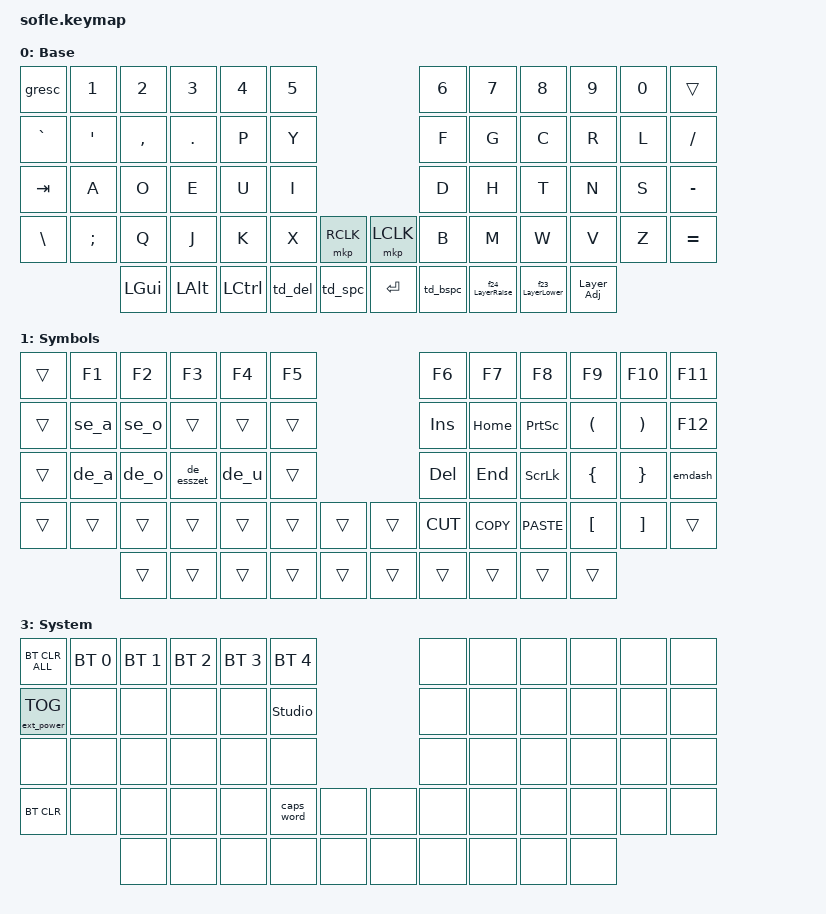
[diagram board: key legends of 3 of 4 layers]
/*
 * Copyright (c) 2020 The ZMK Contributors
 *
 * SPDX-License-Identifier: MIT
 */

#include "keys_se.h"
#include "keys_de.h"
#include "keys_syr.h"
#include "keys_ru.h"
#include <behaviors.dtsi>
#include <dt-bindings/zmk/bt.h>
#include <dt-bindings/zmk/ext_power.h>
#include <dt-bindings/zmk/keys.h>
#include <dt-bindings/zmk/pointing.h>

// Encoders

&sensors { triggers-per-rotation = <30>; };

&left_encoder { steps = <90>; };

&right_encoder { steps = <90>; };

#define BASE 0
#define LOWER 1
#define RAISE 2
#define ADJUST 3

/ {
    // Activate ADJUST layer by pressing raise and lower

    conditional_layers {
        compatible = "zmk,conditional-layers";

        adjust_layer {
            if-layers = <1 2>;
            then-layer = <4>;
        };
    };

    combos {
        compatible = "zmk,combos";

        esc {
            bindings = <&kp ESCAPE>;
            key-positions = <15 14>;
        };
    };

    behaviors {
        caps: caps {
            compatible = "zmk,behavior-caps-word";
            label = "CAPS";
            #binding-cells = <0>;
            continue-list = <POUND MINUS BACKSPACE UNDERSCORE>;
        };

        sp_sh: space_shift {
            compatible = "zmk,behavior-hold-tap";
            #binding-cells = <2>;
            tapping-term-ms = <100>;
            flavor = "balanced";
            bindings = <&kp>, <&kp>;
        };

        td_spc: tap_dance_space {
            compatible = "zmk,behavior-tap-dance";
            #binding-cells = <0>;
            tapping-term-ms = <100>;
            bindings = <&sp_sh LSHFT SPACE>, <&kp CAPS>;
        };

        // Hold-tap for delete: hold = repeat delete, tap = pass through

        ht_del: hold_tap_delete {
            compatible = "zmk,behavior-hold-tap";
            #binding-cells = <2>;
            tapping-term-ms = <200>;
            flavor = "tap-preferred";
            bindings = <&kp>, <&kp>;
        };

        // Tap-dance for delete: tap = DEL, double-tap = Ctrl+DEL

        td_del: tap_dance_delete {
            compatible = "zmk,behavior-tap-dance";
            #binding-cells = <0>;
            tapping-term-ms = <170>;
            bindings = <&ht_del DEL DEL>, <&kp LC(DEL)>;
        };

        // Tap-dance for backspace: tap = BSPC, double-tap = Ctrl+BSPC

        td_bspc: tap_dance_backspace {
            compatible = "zmk,behavior-tap-dance";
            #binding-cells = <0>;
            tapping-term-ms = <150>;
            bindings = <&ht_del BSPC BSPC>, <&kp LC(BSPC)>;
        };
    };

    macros {
        de_a: de_a {
            compatible = "zmk,behavior-macro";
            #binding-cells = <0>;
            bindings = <&kp RIGHT_ALT &kp A>;
            label = "DE_A";
        };

        de_o: de_o {
            compatible = "zmk,behavior-macro";
            #binding-cells = <0>;
            bindings = <&kp RIGHT_ALT &kp O>;
            label = "DE_O";
        };

        de_esszet: de_esszet {
            compatible = "zmk,behavior-macro";
            #binding-cells = <0>;
            bindings = <&kp RIGHT_ALT &kp E>;
            label = "DE_ESSZET";
        };

        de_u: de_u {
            compatible = "zmk,behavior-macro";
            #binding-cells = <0>;
            bindings = <&kp RIGHT_ALT &kp U>;
            label = "DE_U";
        };

        se_o: se_o {
            compatible = "zmk,behavior-macro";
            #binding-cells = <0>;
            bindings = <&kp RIGHT_ALT &kp PERIOD &kp O>;
            label = "SE_O";
        };

        se_a: se_a {
            compatible = "zmk,behavior-macro";
            #binding-cells = <0>;
            bindings = <&kp RIGHT_ALT &kp PERIOD &kp A>;
            label = "SE_A";
        };

        // Letters A-Z

        as_a: as_a {
            compatible = "zmk,behavior-macro";
            #binding-cells = <0>;
            bindings = <&kp LEFT_ALT &kp LEFT_SHIFT &kp A>;
            label = "AS_A";
        };

        as_b: as_b {
            compatible = "zmk,behavior-macro";
            #binding-cells = <0>;
            bindings = <&kp LEFT_ALT &kp LEFT_SHIFT &kp B>;
            label = "AS_B";
        };

        as_c: as_c {
            compatible = "zmk,behavior-macro";
            #binding-cells = <0>;
            bindings = <&kp LEFT_ALT &kp LEFT_SHIFT &kp C>;
            label = "AS_C";
        };

        as_d: as_d {
            compatible = "zmk,behavior-macro";
            #binding-cells = <0>;
            bindings = <&kp LEFT_ALT &kp LEFT_SHIFT &kp D>;
            label = "AS_D";
        };

        as_e: as_e {
            compatible = "zmk,behavior-macro";
            #binding-cells = <0>;
            bindings = <&kp LEFT_ALT &kp LEFT_SHIFT &kp E>;
            label = "AS_E";
        };

        as_f: as_f {
            compatible = "zmk,behavior-macro";
            #binding-cells = <0>;
            bindings = <&kp LEFT_ALT &kp LEFT_SHIFT &kp F>;
            label = "AS_F";
        };

        as_g: as_g {
            compatible = "zmk,behavior-macro";
            #binding-cells = <0>;
            bindings = <&kp LEFT_ALT &kp LEFT_SHIFT &kp G>;
            label = "AS_G";
        };

        as_h: as_h {
            compatible = "zmk,behavior-macro";
            #binding-cells = <0>;
            bindings = <&kp LEFT_ALT &kp LEFT_SHIFT &kp H>;
            label = "AS_H";
        };

        as_i: as_i {
            compatible = "zmk,behavior-macro";
            #binding-cells = <0>;
            bindings = <&kp LEFT_ALT &kp LEFT_SHIFT &kp I>;
            label = "AS_I";
        };

        as_j: as_j {
            compatible = "zmk,behavior-macro";
            #binding-cells = <0>;
            bindings = <&kp LEFT_ALT &kp LEFT_SHIFT &kp J>;
            label = "AS_J";
        };

        as_k: as_k {
            compatible = "zmk,behavior-macro";
            #binding-cells = <0>;
            bindings = <&kp LEFT_ALT &kp LEFT_SHIFT &kp K>;
            label = "AS_K";
        };

        as_l: as_l {
            compatible = "zmk,behavior-macro";
            #binding-cells = <0>;
            bindings = <&kp LEFT_ALT &kp LEFT_SHIFT &kp L>;
            label = "AS_L";
        };

        as_m: as_m {
            compatible = "zmk,behavior-macro";
            #binding-cells = <0>;
            bindings = <&kp LEFT_ALT &kp LEFT_SHIFT &kp M>;
            label = "AS_M";
        };

        as_n: as_n {
            compatible = "zmk,behavior-macro";
            #binding-cells = <0>;
            bindings = <&kp LEFT_ALT &kp LEFT_SHIFT &kp N>;
            label = "AS_N";
        };

        as_o: as_o {
            compatible = "zmk,behavior-macro";
            #binding-cells = <0>;
            bindings = <&kp LEFT_ALT &kp LEFT_SHIFT &kp O>;
            label = "AS_O";
        };

        as_p: as_p {
            compatible = "zmk,behavior-macro";
            #binding-cells = <0>;
            bindings = <&kp LEFT_ALT &kp LEFT_SHIFT &kp P>;
            label = "AS_P";
        };

        as_q: as_q {
            compatible = "zmk,behavior-macro";
            #binding-cells = <0>;
            bindings = <&kp LEFT_ALT &kp LEFT_SHIFT &kp Q>;
            label = "AS_Q";
        };

        as_r: as_r {
            compatible = "zmk,behavior-macro";
            #binding-cells = <0>;
            bindings = <&kp LEFT_ALT &kp LEFT_SHIFT &kp R>;
            label = "AS_R";
        };

        as_s: as_s {
            compatible = "zmk,behavior-macro";
            #binding-cells = <0>;
            bindings = <&kp LEFT_ALT &kp LEFT_SHIFT &kp S>;
            label = "AS_S";
        };

        as_t: as_t {
            compatible = "zmk,behavior-macro";
            #binding-cells = <0>;
            bindings = <&kp LEFT_ALT &kp LEFT_SHIFT &kp T>;
            label = "AS_T";
        };

        as_u: as_u {
            compatible = "zmk,behavior-macro";
            #binding-cells = <0>;
            bindings = <&kp LEFT_ALT &kp LEFT_SHIFT &kp U>;
            label = "AS_U";
        };

        as_v: as_v {
            compatible = "zmk,behavior-macro";
            #binding-cells = <0>;
            bindings = <&kp LEFT_ALT &kp LEFT_SHIFT &kp V>;
            label = "AS_V";
        };

        as_w: as_w {
            compatible = "zmk,behavior-macro";
            #binding-cells = <0>;
            bindings = <&kp LEFT_ALT &kp LEFT_SHIFT &kp W>;
            label = "AS_W";
        };

        as_x: as_x {
            compatible = "zmk,behavior-macro";
            #binding-cells = <0>;
            bindings = <&kp LEFT_ALT &kp LEFT_SHIFT &kp X>;
            label = "AS_X";
        };

        as_y: as_y {
            compatible = "zmk,behavior-macro";
            #binding-cells = <0>;
            bindings = <&kp LEFT_ALT &kp LEFT_SHIFT &kp Y>;
            label = "AS_Y";
        };

        as_z: as_z {
            compatible = "zmk,behavior-macro";
            #binding-cells = <0>;
            bindings = <&kp LEFT_ALT &kp LEFT_SHIFT &kp Z>;
            label = "AS_Z";
        };

        // Numbers 0-9

        as_1: as_1 {
            compatible = "zmk,behavior-macro";
            #binding-cells = <0>;
            bindings = <&kp LEFT_ALT &kp LEFT_SHIFT &kp N1>;
            label = "AS_1";
        };

        as_2: as_2 {
            compatible = "zmk,behavior-macro";
            #binding-cells = <0>;
            bindings = <&kp LEFT_ALT &kp LEFT_SHIFT &kp N2>;
            label = "AS_2";
        };

        as_3: as_3 {
            compatible = "zmk,behavior-macro";
            #binding-cells = <0>;
            bindings = <&kp LEFT_ALT &kp LEFT_SHIFT &kp N3>;
            label = "AS_3";
        };

        as_4: as_4 {
            compatible = "zmk,behavior-macro";
            #binding-cells = <0>;
            bindings = <&kp LEFT_ALT &kp LEFT_SHIFT &kp N4>;
            label = "AS_4";
        };

        as_5: as_5 {
            compatible = "zmk,behavior-macro";
            #binding-cells = <0>;
            bindings = <&kp LEFT_ALT &kp LEFT_SHIFT &kp N5>;
            label = "AS_5";
        };

        as_6: as_6 {
            compatible = "zmk,behavior-macro";
            #binding-cells = <0>;
            bindings = <&kp LEFT_ALT &kp LEFT_SHIFT &kp N6>;
            label = "AS_6";
        };

        as_7: as_7 {
            compatible = "zmk,behavior-macro";
            #binding-cells = <0>;
            bindings = <&kp LEFT_ALT &kp LEFT_SHIFT &kp N7>;
            label = "AS_7";
        };

        as_8: as_8 {
            compatible = "zmk,behavior-macro";
            #binding-cells = <0>;
            bindings = <&kp LEFT_ALT &kp LEFT_SHIFT &kp N8>;
            label = "AS_8";
        };

        as_9: as_9 {
            compatible = "zmk,behavior-macro";
            #binding-cells = <0>;
            bindings = <&kp LEFT_ALT &kp LEFT_SHIFT &kp N9>;
            label = "AS_9";
        };

        as_0: as_0 {
            compatible = "zmk,behavior-macro";
            #binding-cells = <0>;
            bindings = <&kp LEFT_ALT &kp LEFT_SHIFT &kp N0>;
            label = "AS_0";
        };

        // Symbol keys

        as_minus: as_minus {
            compatible = "zmk,behavior-macro";
            #binding-cells = <0>;
            bindings = <&kp LEFT_ALT &kp LEFT_SHIFT &kp MINUS>;
            label = "AS_MINUS";
        };

        as_equal: as_equal {
            compatible = "zmk,behavior-macro";
            #binding-cells = <0>;
            bindings = <&kp LEFT_ALT &kp LEFT_SHIFT &kp EQUAL>;
            label = "AS_EQUAL";
        };

        as_lbkt: as_lbkt {
            compatible = "zmk,behavior-macro";
            #binding-cells = <0>;
            bindings = <&kp LEFT_ALT &kp LEFT_SHIFT &kp LBKT>;
            label = "AS_LBKT";
        };

        as_rbkt: as_rbkt {
            compatible = "zmk,behavior-macro";
            #binding-cells = <0>;
            bindings = <&kp LEFT_ALT &kp LEFT_SHIFT &kp RBKT>;
            label = "AS_RBKT";
        };

        as_bslh: as_bslh {
            compatible = "zmk,behavior-macro";
            #binding-cells = <0>;
            bindings = <&kp LEFT_ALT &kp LEFT_SHIFT &kp BSLH>;
            label = "AS_BSLH";
        };

        as_semi: as_semi {
            compatible = "zmk,behavior-macro";
            #binding-cells = <0>;
            bindings = <&kp LEFT_ALT &kp LEFT_SHIFT &kp SEMI>;
            label = "AS_SEMI";
        };

        as_sqt: as_sqt {
            compatible = "zmk,behavior-macro";
            #binding-cells = <0>;
            bindings = <&kp LEFT_ALT &kp LEFT_SHIFT &kp SQT>;
            label = "AS_SQT";
        };

        as_grave: as_grave {
            compatible = "zmk,behavior-macro";
            #binding-cells = <0>;
            bindings = <&kp LEFT_ALT &kp LEFT_SHIFT &kp GRAVE>;
            label = "AS_GRAVE";
        };

        as_comma: as_comma {
            compatible = "zmk,behavior-macro";
            #binding-cells = <0>;
            bindings = <&kp LEFT_ALT &kp LEFT_SHIFT &kp COMMA>;
            label = "AS_COMMA";
        };

        as_period: as_period {
            compatible = "zmk,behavior-macro";
            #binding-cells = <0>;
            bindings = <&kp LEFT_ALT &kp LEFT_SHIFT &kp PERIOD>;
            label = "AS_PERIOD";
        };

        as_slash: as_slash {
            compatible = "zmk,behavior-macro";
            #binding-cells = <0>;
            bindings = <&kp LEFT_ALT &kp LEFT_SHIFT &kp SLASH>;
            label = "AS_SLASH";
        };

        // Function keys F1-F12

        as_f1: as_f1 {
            compatible = "zmk,behavior-macro";
            #binding-cells = <0>;
            bindings = <&kp LEFT_ALT &kp LEFT_SHIFT &kp F1>;
            label = "AS_F1";
        };

        as_f2: as_f2 {
            compatible = "zmk,behavior-macro";
            #binding-cells = <0>;
            bindings = <&kp LEFT_ALT &kp LEFT_SHIFT &kp F2>;
            label = "AS_F2";
        };

        as_f3: as_f3 {
            compatible = "zmk,behavior-macro";
            #binding-cells = <0>;
            bindings = <&kp LEFT_ALT &kp LEFT_SHIFT &kp F3>;
            label = "AS_F3";
        };

        as_f4: as_f4 {
            compatible = "zmk,behavior-macro";
            #binding-cells = <0>;
            bindings = <&kp LEFT_ALT &kp LEFT_SHIFT &kp F4>;
            label = "AS_F4";
        };

        as_f5: as_f5 {
            compatible = "zmk,behavior-macro";
            #binding-cells = <0>;
            bindings = <&kp LEFT_ALT &kp LEFT_SHIFT &kp F5>;
            label = "AS_F5";
        };

        as_f6: as_f6 {
            compatible = "zmk,behavior-macro";
            #binding-cells = <0>;
            bindings = <&kp LEFT_ALT &kp LEFT_SHIFT &kp F6>;
            label = "AS_F6";
        };

        as_f7: as_f7 {
            compatible = "zmk,behavior-macro";
            #binding-cells = <0>;
            bindings = <&kp LEFT_ALT &kp LEFT_SHIFT &kp F7>;
            label = "AS_F7";
        };

        as_f8: as_f8 {
            compatible = "zmk,behavior-macro";
            #binding-cells = <0>;
            bindings = <&kp LEFT_ALT &kp LEFT_SHIFT &kp F8>;
            label = "AS_F8";
        };

        as_f9: as_f9 {
            compatible = "zmk,behavior-macro";
            #binding-cells = <0>;
            bindings = <&kp LEFT_ALT &kp LEFT_SHIFT &kp F9>;
            label = "AS_F9";
        };

        as_f10: as_f10 {
            compatible = "zmk,behavior-macro";
            #binding-cells = <0>;
            bindings = <&kp LEFT_ALT &kp LEFT_SHIFT &kp F10>;
            label = "AS_F10";
        };

        as_f11: as_f11 {
            compatible = "zmk,behavior-macro";
            #binding-cells = <0>;
            bindings = <&kp LEFT_ALT &kp LEFT_SHIFT &kp F11>;
            label = "AS_F11";
        };

        as_f12: as_f12 {
            compatible = "zmk,behavior-macro";
            #binding-cells = <0>;
            bindings = <&kp LEFT_ALT &kp LEFT_SHIFT &kp F12>;
            label = "AS_F12";
        };

        // Special keys

        as_tab: as_tab {
            compatible = "zmk,behavior-macro";
            #binding-cells = <0>;
            bindings = <&kp LEFT_ALT &kp LEFT_SHIFT &kp TAB>;
            label = "AS_TAB";
        };

        as_space: as_space {
            compatible = "zmk,behavior-macro";
            #binding-cells = <0>;
            bindings = <&kp LEFT_ALT &kp LEFT_SHIFT &kp SPACE>;
            label = "AS_SPACE";
        };

        as_enter: as_enter {
            compatible = "zmk,behavior-macro";
            #binding-cells = <0>;
            bindings = <&kp LEFT_ALT &kp LEFT_SHIFT &kp ENTER>;
            label = "AS_ENTER";
        };

        as_bspc: as_bspc {
            compatible = "zmk,behavior-macro";
            #binding-cells = <0>;
            bindings = <&kp LEFT_ALT &kp LEFT_SHIFT &kp BSPC>;
            label = "AS_BSPC";
        };

        as_del: as_del {
            compatible = "zmk,behavior-macro";
            #binding-cells = <0>;
            bindings = <&kp LEFT_ALT &kp LEFT_SHIFT &kp DEL>;
            label = "AS_DEL";
        };

        as_esc: as_esc {
            compatible = "zmk,behavior-macro";
            #binding-cells = <0>;
            bindings = <&kp LEFT_ALT &kp LEFT_SHIFT &kp ESC>;
            label = "AS_ESC";
        };

        // Arrow keys

        as_up: as_up {
            compatible = "zmk,behavior-macro";
            #binding-cells = <0>;
            bindings = <&kp LEFT_ALT &kp LEFT_SHIFT &kp UP>;
            label = "AS_UP";
        };

        as_down: as_down {
            compatible = "zmk,behavior-macro";
            #binding-cells = <0>;
            bindings = <&kp LEFT_ALT &kp LEFT_SHIFT &kp DOWN>;
            label = "AS_DOWN";
        };

        as_left: as_left {
            compatible = "zmk,behavior-macro";
            #binding-cells = <0>;
            bindings = <&kp LEFT_ALT &kp LEFT_SHIFT &kp LEFT>;
            label = "AS_LEFT";
        };

        as_right: as_right {
            compatible = "zmk,behavior-macro";
            #binding-cells = <0>;
            bindings = <&kp LEFT_ALT &kp LEFT_SHIFT &kp RIGHT>;
            label = "AS_RIGHT";
        };

        // Page/Home/End keys

        as_home: as_home {
            compatible = "zmk,behavior-macro";
            #binding-cells = <0>;
            bindings = <&kp LEFT_ALT &kp LEFT_SHIFT &kp HOME>;
            label = "AS_HOME";
        };

        as_end: as_end {
            compatible = "zmk,behavior-macro";
            #binding-cells = <0>;
            bindings = <&kp LEFT_ALT &kp LEFT_SHIFT &kp END>;
            label = "AS_END";
        };

        as_pg_up: as_pg_up {
            compatible = "zmk,behavior-macro";
            #binding-cells = <0>;
            bindings = <&kp LEFT_ALT &kp LEFT_SHIFT &kp PG_UP>;
            label = "AS_PG_UP";
        };

        as_pg_dn: as_pg_dn {
            compatible = "zmk,behavior-macro";
            #binding-cells = <0>;
            bindings = <&kp LEFT_ALT &kp LEFT_SHIFT &kp PG_DN>;
            label = "AS_PG_DN";
        };

        // Insert key

        as_ins: as_ins {
            compatible = "zmk,behavior-macro";
            #binding-cells = <0>;
            bindings = <&kp LEFT_ALT &kp LEFT_SHIFT &kp INS>;
            label = "AS_INS";
        };

        altf4: altf4 {
            compatible = "zmk,behavior-macro";
            #binding-cells = <0>;
            bindings = <&kp LEFT_ALT &kp F4>;
            label = "ALTF4";
        };

        altf2: altf2 {
            compatible = "zmk,behavior-macro";
            #binding-cells = <0>;
            bindings = <&kp LEFT_ALT &kp F2>;
            label = "ALTF2";
        };

        emdash: emdash {
            compatible = "zmk,behavior-macro";
            #binding-cells = <0>;
            bindings = <&kp RIGHT_ALT &kp MINUS>;
            label = "EMDASH";
        };

        f24_LayerRaise: f24_LayerRaise {
            compatible = "zmk,behavior-macro";
            #binding-cells = <0>;
            bindings =
                <&macro_press>,
                <&kp F24>,
                <&macro_press>,
                <&mo 1>,
                <&macro_pause_for_release>,
                <&macro_release>,
                <&mo 1>,
                <&macro_release>,
                <&kp F24>;

            label = "F24_LAYERRAISE";
        };

        f23_LayerLower: f23_LayerLower {
            compatible = "zmk,behavior-macro";
            #binding-cells = <0>;
            bindings =
                <&macro_press>,
                <&kp F23>,
                <&macro_press>,
                <&mo 2>,
                <&macro_pause_for_release>,
                <&macro_release>,
                <&mo 2>,
                <&macro_release>,
                <&kp F23>;

            label = "F23_LAYERLOWER";
        };

        Layer_Adj: Layer_Adj {
            compatible = "zmk,behavior-macro";
            #binding-cells = <0>;
            bindings =
                <&macro_press>,
                <&kp F22>,
                <&macro_press>,
                <&mo 3>,
                <&macro_pause_for_release>,
                <&macro_release>,
                <&mo 3>,
                <&macro_release>,
                <&kp F22>;

            label = "LAYER_ADJ";
        };
    };

    keymap {
        compatible = "zmk,keymap";

        default_layer {
            display-name = "Base";

            // ------------------------------------------------------------------------------------------------------------
            // |   `   |  1  |  2  |  3   |  4   |  5   |                   |  6   |  7    |  8    |  9   |   0   |       |
            // |  ESC  |  Q  |  W  |  E   |  R   |  T   |                   |  Y   |  U    |  I    |  O   |   P   | BKSPC |
            // |  TAB  |  A  |  S  |  D   |  F   |  G   |                   |  H   |  J    |  K    |  L   |   ;   |   '   |
            // | SHIFT |  Z  |  X  |  C   |  V   |  B   |  MUTE  |  |       |  N   |  M    |  ,    |  .   |   /   | SHIFT |
            //               | GUI | ALT  | CTRL | LOWER|  ENTER |  | SPACE | RAISE| CTRL  | ALT   | GUI  |

            bindings = <
&gresc         &kp N1    &kp N2     &kp N3      &kp N4     &kp N5                           &kp N6    &kp N7           &kp N8           &kp N9      &kp N0  &trans
&kp GRAVE      &kp APOS  &kp COMMA  &kp PERIOD  &kp P      &kp Y                            &kp F     &kp G            &kp C            &kp R       &kp L   &kp FSLH
&kp TAB        &kp A     &kp O      &kp E       &kp U      &kp I                            &kp D     &kp H            &kp T            &kp N       &kp S   &kp MINUS
&kp BACKSLASH  &kp SEMI  &kp Q      &kp J       &kp K      &kp X    &mkp RCLK    &mkp LCLK  &kp B     &kp M            &kp W            &kp V       &kp Z   &kp EQUAL
                         &kp LGUI   &kp LALT    &kp LCTRL  &td_del  &td_spc      &kp ENTER  &td_bspc  &f24_LayerRaise  &f23_LayerLower  &Layer_Adj
            >;

            sensor-bindings =
                <&inc_dec_kp RIGHT_ARROW LEFT_ARROW>,
                <&inc_dec_kp DOWN_ARROW UP_ARROW>;
        };

        lower_layer {
            display-name = "Symbols";

            // TODO: Some binds are waiting for shifted keycode support.
            // ------------------------------------------------------------------------------------------------------------
            // |       |  F1 |  F2 |  F3  |  F4  |  F5  |                   |  F6  |  F7   |  F8   |  F9  |  F10  |  F11  |
            // |   `   |  1  |  2  |  3   |  4   |  5   |                   |  6   |  7    |  8    |  9   |   0   |  F12  |
            // |       |  !  |  @  |  #   |  $   |  %   |                   |  ^   |  &    |  *    |  (   |   )   |   |   |
            // |       |  =  |  -  |  +   |  {   |  }   |        |  |       |  [   |  ]    |  ;    |  :   |   \   |       |
            //               |     |      |      |      |        |  |       |      |       |       |      |

            bindings = <
&trans  &kp F1  &kp F2  &kp F3      &kp F4  &kp F5                    &kp F6      &kp F7      &kp F8           &kp F9                &kp F10                &kp F11
&trans  &se_a   &se_o   &trans      &trans  &trans                    &kp INS     &kp HOME    &kp PRINTSCREEN  &kp LEFT_PARENTHESIS  &kp RIGHT_PARENTHESIS  &kp F12
&trans  &de_a   &de_o   &de_esszet  &de_u   &trans                    &kp DELETE  &kp END     &kp SCROLLLOCK   &kp LEFT_BRACE        &kp RIGHT_BRACE        &emdash
&trans  &trans  &trans  &trans      &trans  &trans  &trans    &trans  &kp K_CUT   &kp K_COPY  &kp K_PASTE      &kp LEFT_BRACKET      &kp RIGHT_BRACKET      &trans
                &trans  &trans      &trans  &trans  &trans    &trans  &trans      &trans      &trans           &trans
            >;

            sensor-bindings =
                <&inc_dec_kp K_UNDO K_REDO>,
                <&inc_dec_kp PAGE_UP PAGE_DOWN>;
        };

        raise_layer {
            display-name = "stinkybutts";

            // ------------------------------------------------------------------------------------------------------------
            // | BTCLR | BT1  | BT2  |  BT3  |  BT4  |  BT5 |                |      |      |       |      |       |       |
            // |       | INS  | PSCR | GUI   |       |      |                | PGUP |      |   ^   |      |       |       |
            // |       | ALT  | CTRL | SHIFT |       | CAPS |                | PGDN |   <- |   v   |  ->  |  DEL  | BKSPC |
            // |       | UNDO | CUT  | COPY  | PASTE |      |      |  |      |      |      |       |      |       |       |
            //                |      |       |       |      |      |  |      |      |      |       |      |

            bindings = <
&as_esc    &as_1            &kp KP_NUMLOCK   &as_f3           &as_4            &as_5                                   &kp SYR_SYRIAC_SUBLINEAR_COLON_SKEWED_RIGHT  &trans  &kp KP_NUMBER_0  &kp PERIOD       &kp KP_NUM       &kp ASTRK
&as_grave  &as_sqt          &kp KP_NUMBER_7  &kp KP_NUMBER_8  &kp KP_N9        &as_y                                   &kp SYR_WEST_SYRIAC_CROSS                    &trans  &kp KP_NUMBER_7  &kp KP_NUMBER_8  &kp KP_NUMBER_9  &kp KP_DIVIDE
&as_tab    &kp KP_NUMBER_0  &kp KP_N4        &kp KP_NUMBER_5  &kp KP_NUMBER_6  &as_i                                   &kp RU_CYRILLIC_HARD_SIGN                    &trans  &kp KP_NUMBER_4  &kp KP_NUMBER_5  &kp KP_NUMBER_6  &kp KP_MINUS
&as_ins    &trans           &kp KP_NUMBER_1  &kp KP_NUMBER_2  &kp KP_NUMBER_3  &as_x   &kp K_MUTE    &kp K_PLAY_PAUSE  &kp RU_RUBLE                                 &trans  &kp KP_NUMBER_1  &kp KP_NUMBER_2  &kp KP_NUMBER_3  &kp KP_PLUS
                            &trans           &trans           &trans           &trans  &trans        &trans            &trans                                       &trans
            >;

            sensor-bindings =
                <&inc_dec_kp C_VOL_UP C_VOL_DN>,
                <&inc_dec_kp K_NEXT K_PREV>;
        };

        adjust_layer {
            // ----------------------------------------------------------------------------------------------------------------------------
            // | BTCLR  |  BT1    |  BT2    |   BT3   |   BT4   |   BT5   |                  |      |      |       |      |       |       |
            // | EXTPWR | RGB_HUD | RGB_HUI | RGB_SAD | RGB_SAI | RGB_EFF |                  |      |      |       |      |       |       |
            // |        | RGB_BRD | RGB_BRI |         |         |         |                  |      |      |       |      |       |       |
            // |        |         |         |         |         |         | RGB_TOG | |      |      |      |       |      |       |       |
            //                    |         |         |         |         |         | |      |      |      |       |      |

            display-name = "System";
            bindings = <
&bt BT_CLR_ALL     &bt BT_SEL 0  &bt BT_SEL 1  &bt BT_SEL 2  &bt BT_SEL 3  &bt BT_SEL 4                    &none  &none  &none  &none  &none  &none
&ext_power EP_TOG  &none         &none         &none         &none         &studio_unlock                  &none  &none  &none  &none  &none  &none
&none              &none         &none         &none         &none         &none                           &none  &none  &none  &none  &none  &none
&bt BT_CLR         &none         &none         &none         &none         &caps_word      &none    &none  &none  &none  &none  &none  &none  &none
                                 &none         &none         &none         &none           &none    &none  &none  &none  &none  &none
            >;
        };
    };
};
